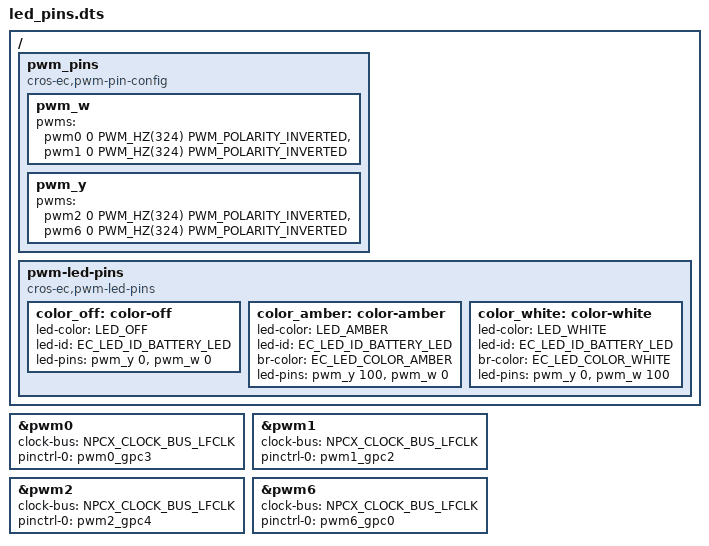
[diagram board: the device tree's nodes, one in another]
/* Copyright 2022 The Chromium OS Authors. All rights reserved.
 * Use of this source code is governed by a BSD-style license that can be
 * found in the LICENSE file.
 */

/ {
	pwm_pins {
		compatible = "cros-ec,pwm-pin-config";
		pwm_w: pwm_w {
			#led-pin-cells = <1>;
			pwms = <&pwm0 0 PWM_HZ(324) PWM_POLARITY_INVERTED
				&pwm1 0 PWM_HZ(324) PWM_POLARITY_INVERTED>;
		};

		pwm_y: pwm_y {
			#led-pin-cells = <1>;
			pwms = <&pwm2 0 PWM_HZ(324) PWM_POLARITY_INVERTED
				&pwm6 0 PWM_HZ(324) PWM_POLARITY_INVERTED>;
		};
	};

	pwm-led-pins {
		compatible = "cros-ec,pwm-led-pins";

		color_off: color-off {
			led-color = "LED_OFF";
			led-id = "EC_LED_ID_BATTERY_LED";
			led-pins = <&pwm_y 0>,
				   <&pwm_w 0>;
		};

		color_amber: color-amber {
			led-color = "LED_AMBER";
			led-id = "EC_LED_ID_BATTERY_LED";
			br-color = "EC_LED_COLOR_AMBER";
			led-pins = <&pwm_y 100>,
				   <&pwm_w 0>;
		};

		color_white: color-white {
			led-color = "LED_WHITE";
			led-id = "EC_LED_ID_BATTERY_LED";
			br-color = "EC_LED_COLOR_WHITE";
			led-pins = <&pwm_y 0>,
				   <&pwm_w 100>;
		};
	};
};

/* LED2 */
&pwm0 {
	status = "okay";
	clock-bus = "NPCX_CLOCK_BUS_LFCLK";
	pinctrl-0 = <&pwm0_gpc3>;
	pinctrl-names = "default";
};

/* LED3 */
&pwm1 {
	status = "okay";
	clock-bus = "NPCX_CLOCK_BUS_LFCLK";
	pinctrl-0 = <&pwm1_gpc2>;
	pinctrl-names = "default";
};

/* LED1 */
&pwm2 {
	status = "okay";
	clock-bus = "NPCX_CLOCK_BUS_LFCLK";
	pinctrl-0 = <&pwm2_gpc4>;
	pinctrl-names = "default";
};

/* LED0 */
&pwm6 {
	status = "okay";
	clock-bus = "NPCX_CLOCK_BUS_LFCLK";
	pinctrl-0 = <&pwm6_gpc0>;
	pinctrl-names = "default";
};
